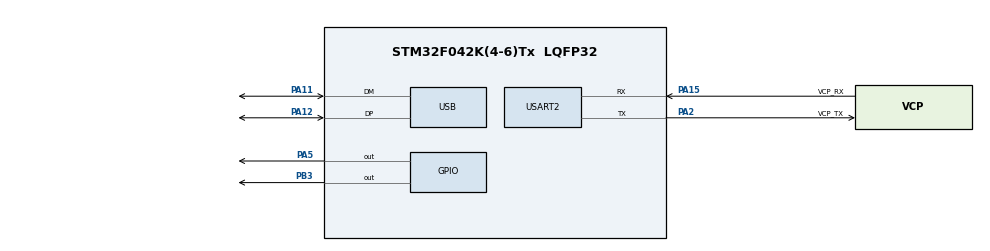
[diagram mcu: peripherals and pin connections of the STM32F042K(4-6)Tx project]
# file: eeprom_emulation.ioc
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Mcu.Family=STM32F0
Mcu.Name=STM32F042K(4-6)Tx
Mcu.Package=LQFP32
PA11.Mode=Device
PA11.Signal=USB_DM
PA12.Mode=Device
PA12.Signal=USB_DP
PA13.GPIO_Label=SWDIO
PA13.Mode=Serial_Wire
PA13.Signal=SYS_SWDIO
PA14.GPIO_Label=SWCLK
PA14.Mode=Serial_Wire
PA14.Signal=SYS_SWCLK
PA15.GPIO_Label=VCP_RX
PA15.Mode=Asynchronous
PA15.Signal=USART2_RX
PA2.GPIO_Label=VCP_TX
PA2.Mode=Asynchronous
PA2.Signal=USART2_TX
PA5.Signal=GPIO_Output
PB3.Signal=GPIO_Output
PF0-OSC_IN.GPIO_Label=MCO
PF0-OSC_IN.Mode=HSE-External-Clock-Source
PF0-OSC_IN.Signal=RCC_OSC_IN
ProjectManager.HeapSize=0x200
ProjectManager.StackSize=0x400
ProjectManager.TargetToolchain=STM32CubeIDE
USART2.VirtualMode-Asynchronous=VM_ASYNC
board=NUCLEO-F042K6

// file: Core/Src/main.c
/* USER CODE BEGIN Header */
/**
  ******************************************************************************
  * @file           : main.c
  * @brief          : Main program body
  ******************************************************************************
  * @attention
  *
  * Copyright (c) 2025 STMicroelectronics.
  * All rights reserved.
  *
  * This software is licensed under terms that can be found in the LICENSE file
  * in the root directory of this software component.
  * If no LICENSE file comes with this software, it is provided AS-IS.
  *
  ******************************************************************************
  */
/* USER CODE END Header */
#include "main.h"
#include <stdio.h> // Make sure to include this

#include "stm32f0xx_hal.h"
//#define FLASH_PAGE_SIZE         1024U
#define FLASH_END_ADDRESS       0x08007FFFU
#define FLASH_STORAGE_ADDRESS   (FLASH_END_ADDRESS - FLASH_PAGE_SIZE + 1U)

// Function declarations (prototypes)
uint32_t find_last_written_address(void);
void erase_storage_page(void);
uint8_t Flash_Append(uint16_t data);
uint16_t Flash_ReadLastValue(void);

uint8_t Flash_Append(uint16_t data)
{
    uint32_t address = find_last_written_address();

    // Page full? Erase and restart
    if (address >= (FLASH_STORAGE_ADDRESS + FLASH_PAGE_SIZE)) {
        erase_storage_page();
        address = FLASH_STORAGE_ADDRESS;
    }

    HAL_FLASH_Unlock();
    HAL_StatusTypeDef result = HAL_FLASH_Program(FLASH_TYPEPROGRAM_HALFWORD, address, data);
    HAL_FLASH_Lock();

    return (result == HAL_OK) ? 0 : 1;
}

uint32_t find_last_written_address(void)
{
    uint32_t address = FLASH_STORAGE_ADDRESS;
    while (address < (FLASH_STORAGE_ADDRESS + FLASH_PAGE_SIZE))
    {
        uint16_t value = *(volatile uint16_t*)address;
        if (value == 0xFFFF)
            break;
        address += 2;
    }
    return address;
}

uint16_t Flash_ReadLastValue(void)
{
    uint32_t address = find_last_written_address();

    if (address == FLASH_STORAGE_ADDRESS)
        return 0xFFFF;  // Nothing written yet

    return *(volatile uint16_t*)(address - 2);  // Last written value
}

void erase_storage_page(void)
{
    HAL_FLASH_Unlock();
    FLASH_EraseInitTypeDef erase;
    uint32_t page_error;

    erase.TypeErase = FLASH_TYPEERASE_PAGES;
    erase.PageAddress = FLASH_STORAGE_ADDRESS;
    erase.NbPages = 1;

    HAL_FLASHEx_Erase(&erase, &page_error);
    HAL_FLASH_Lock();
}

extern UART_HandleTypeDef huart2;

int _write(int file, char *ptr, int len)
{
  HAL_UART_Transmit(&huart2, (uint8_t*)ptr, len, HAL_MAX_DELAY);
  return len;
}

UART_HandleTypeDef huart2;

void SystemClock_Config(void);
static void MX_GPIO_Init(void);
static void MX_USART2_UART_Init(void);

int main(void)
{

  /* MCU Configuration--------------------------------------------------------*/

  /* Reset of all peripherals, Initializes the Flash interface and the Systick. */
  HAL_Init();

  /* Configure the system clock */
  SystemClock_Config();

  /* Initialize all configured peripherals */
  MX_GPIO_Init();
  MX_USART2_UART_Init();

  /* Infinite loop */
  while (1)
    {

      /* USER CODE BEGIN 3 */
      HAL_GPIO_TogglePin(GPIOA, GPIO_PIN_5); // Toggle the LED pin (PA5)
      HAL_GPIO_TogglePin(GPIOB, GPIO_PIN_3); // Toggle the LED pin (PB3)
      printf("LED Toggled! The time is %lu\r\n", HAL_GetTick());
//      HAL_Delay(1000); // Wait for 500 milliseconds (0.5 seconds)
      /* USER CODE END 3 */

      uint16_t last = Flash_ReadLastValue();

	 char msg[32];
	 printf(msg, "Last value: %u\r\n", last);

	 uint16_t next = (last == 0xFFFF) ? 0 : last + 1;

	 if (Flash_Append(next) != 0) {
		 printf("Flash append failed!\r\n");
	 } else {
		 printf("Value written.\r\n");
	 }

	 HAL_Delay(1000);

	 printf("Resetting system.\r\n");
//	 NVIC_SystemReset();
    }
  /* USER CODE END 3 */
}

void SystemClock_Config(void)
{
  RCC_OscInitTypeDef RCC_OscInitStruct = {0};
  RCC_ClkInitTypeDef RCC_ClkInitStruct = {0};

  /** Initializes the RCC Oscillators according to the specified parameters
  * in the RCC_OscInitTypeDef structure.
  */
  RCC_OscInitStruct.OscillatorType = RCC_OSCILLATORTYPE_HSI;
  RCC_OscInitStruct.HSIState = RCC_HSI_ON;
  RCC_OscInitStruct.HSICalibrationValue = RCC_HSICALIBRATION_DEFAULT;
  RCC_OscInitStruct.PLL.PLLState = RCC_PLL_NONE;
  if (HAL_RCC_OscConfig(&RCC_OscInitStruct) != HAL_OK)
  {
    Error_Handler();
  }

  /** Initializes the CPU, AHB and APB buses clocks
  */
  RCC_ClkInitStruct.ClockType = RCC_CLOCKTYPE_HCLK|RCC_CLOCKTYPE_SYSCLK
                              |RCC_CLOCKTYPE_PCLK1;
  RCC_ClkInitStruct.SYSCLKSource = RCC_SYSCLKSOURCE_HSI;
  RCC_ClkInitStruct.AHBCLKDivider = RCC_SYSCLK_DIV1;
  RCC_ClkInitStruct.APB1CLKDivider = RCC_HCLK_DIV1;

  if (HAL_RCC_ClockConfig(&RCC_ClkInitStruct, FLASH_LATENCY_0) != HAL_OK)
  {
    Error_Handler();
  }
}

static void MX_USART2_UART_Init(void)
{

  huart2.Instance = USART2;
  huart2.Init.BaudRate = 38400;
  huart2.Init.WordLength = UART_WORDLENGTH_8B;
  huart2.Init.StopBits = UART_STOPBITS_1;
  huart2.Init.Parity = UART_PARITY_NONE;
  huart2.Init.Mode = UART_MODE_TX_RX;
  huart2.Init.HwFlowCtl = UART_HWCONTROL_NONE;
  huart2.Init.OverSampling = UART_OVERSAMPLING_16;
  huart2.Init.OneBitSampling = UART_ONE_BIT_SAMPLE_DISABLE;
  huart2.AdvancedInit.AdvFeatureInit = UART_ADVFEATURE_NO_INIT;
  if (HAL_UART_Init(&huart2) != HAL_OK)
  {
    Error_Handler();
  }

}

static void MX_GPIO_Init(void)
{
  GPIO_InitTypeDef GPIO_InitStruct = {0};

  /* GPIO Ports Clock Enable */
  __HAL_RCC_GPIOF_CLK_ENABLE();
  __HAL_RCC_GPIOA_CLK_ENABLE();
  __HAL_RCC_GPIOB_CLK_ENABLE();

  /*Configure GPIO pin Output Level */
  HAL_GPIO_WritePin(GPIOA, GPIO_PIN_5, GPIO_PIN_RESET);
  HAL_GPIO_WritePin(GPIOB, GPIO_PIN_3, GPIO_PIN_RESET);

  /*Configure GPIO pin : PA5 */
  GPIO_InitStruct.Pin = GPIO_PIN_5;
  GPIO_InitStruct.Mode = GPIO_MODE_OUTPUT_PP;
  GPIO_InitStruct.Pull = GPIO_NOPULL;
  GPIO_InitStruct.Speed = GPIO_SPEED_FREQ_LOW;
  HAL_GPIO_Init(GPIOA, &GPIO_InitStruct);

  /*Configure GPIO pin : PB3 */
  GPIO_InitStruct.Pin = GPIO_PIN_3;
  GPIO_InitStruct.Mode = GPIO_MODE_OUTPUT_PP;
  GPIO_InitStruct.Pull = GPIO_NOPULL;
  GPIO_InitStruct.Speed = GPIO_SPEED_FREQ_LOW;
  HAL_GPIO_Init(GPIOB, &GPIO_InitStruct);

}

void Error_Handler(void)
{
  __disable_irq();
  while (1)
  {
  }
}
